# CORE_PRM register map
Vendor: Texas Instruments
Peripheral module from a debugger description file (folder omap4430).
Registers are 32-bit, access not given, reset 0x3 unless marked. A register's access mark holds for its fields unless they carry their own. Offsets are as the file gives them; lines under a group give offsets from that group; [hi:lo] are bit positions; {n}, {i} and the like mark numbered series; 'fields as' and 'values as' point back to an identical list; <NAME> marks a mode.

## CORE_PRM
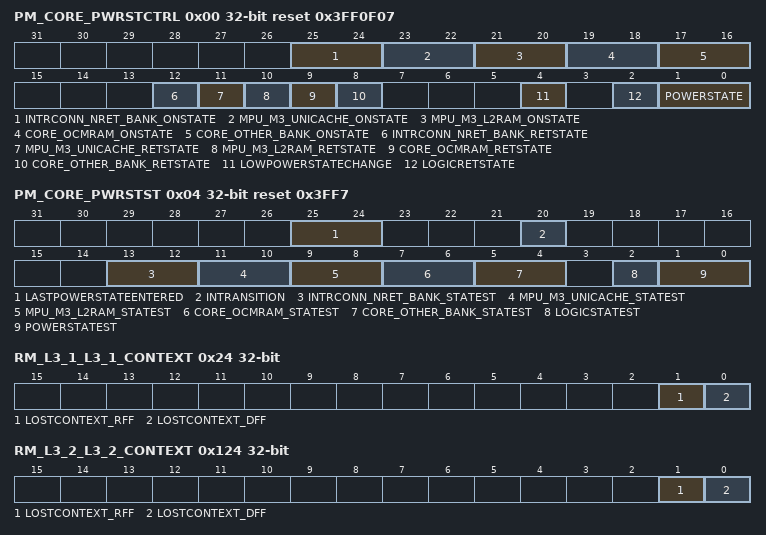
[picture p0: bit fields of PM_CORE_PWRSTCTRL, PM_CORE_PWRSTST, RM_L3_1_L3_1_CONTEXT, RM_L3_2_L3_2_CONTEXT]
0x00 PM_CORE_PWRSTCTRL reset 0x3FF0F07 — This register controls the CORE power state to reach upon a domain sleep transition
  [25:24] INTRCONN_NRET_BANK_ONSTATE — INTRCONN_WP bank and DMM bank2 state when domain is ON. (access R Rreturns1s)
    3=INTRCONN_NRET_BANK_ONSTATE_3_r (Memory bank is on when the domain is ON.)
  [23:22] MPU_M3_UNICACHE_ONSTATE — MPU_A3 UNICACHE bank state when domain is ON. (access R Rreturns1s)
    3=MPU_M3_UNICACHE_ONSTATE_3_r (Memory bank is on when the domain is ON.)
  [21:20] MPU_M3_L2RAM_ONSTATE — MPU_A3 L2 bank state when domain is ON. (access R Rreturns1s)
    3=MPU_M3_L2RAM_ONSTATE_3_r (Memory bank is on when the domain is ON.)
  [19:18] CORE_OCMRAM_ONSTATE — OCMRAM bank state when domain is ON. (access R Rreturns1s)
    3=CORE_OCMRAM_ONSTATE_3_r (Memory bank is on when the domain is ON.)
  [17:16] CORE_OTHER_BANK_ONSTATE — DMA/ICR bank and DMM bank1 state when domain is ON. (access R Rreturns1s)
    3=CORE_OTHER_BANK_ONSTATE_3_r (Memory bank is on when the domain is ON.)
  [12] INTRCONN_NRET_BANK_RETSTATE ro — INTRCONN_WP bank and DMM bank2 state when domain is RETENTION.
    0=INTRCONN_NRET_BANK_RETSTATE_0_r (Memory bank is off when the domain is in the RETENTION state.)
  [11] MPU_M3_UNICACHE_RETSTATE rw — MPU_A3 UNICACHE bank state when domain is RETENTION.
    0=Memory bank is off when the domain is in the RETENTION state; 1=Memory bank is retained when domain is in RETENTION state
  [10] MPU_M3_L2RAM_RETSTATE rw — MPU_A3 L2 bank state when domain is RETENTION.
    values as MPU_M3_UNICACHE_RETSTATE
  [9] CORE_OCMRAM_RETSTATE — OCMRAM bank state when domain is RETENTION. (access R Rreturns1s)
    1=CORE_OCMRAM_RETSTATE_1_r (Memory bank is retained when domain is in RETENTION state.)
  [8] CORE_OTHER_BANK_RETSTATE — DMA/ICR bank and DMM bank1 state when domain is RETENTION. (access R Rreturns1s)
    1=CORE_OTHER_BANK_RETSTATE_1_r (Memory bank is retained when domain is in RETENTION state.)
  [4] LOWPOWERSTATECHANGE — Power state change request when domain has already performed a sleep transition. Allows going into deeper low power state without waking up the power domain. (access RW WSpecial)
    0=Do not request a low power state change; 1=Request a low power state change. This bit is automatically cleared when the power state is effectively changed or when power state is ON.
  [2] LOGICRETSTATE rw — Logic state when power domain is RETENTION
    0=Only retention registers are retained and remaing logic is off when the domain is in RETENTION state; 1=Whole logic is retained when domain is in RETENTION state
  [1:0] POWERSTATE rw — Power state control
    0=POWERSTATE_0_r (Reserved); 1=RETENTION state; 2=INACTIVE state; 3=ON State
0x04 PM_CORE_PWRSTST reset 0x3FF7 — This register provides a status on the current CORE power domain state. [warm reset insensitive]
  [25:24] LASTPOWERSTATEENTERED — Last low power state entered. Set to 0x3 upon write of the same only. This register is intended for debug purpose only. (access RW W1toSet)
    3=LASTPOWERSTATEENTERED_3_r (Power domain was previously ON-ACTIVE); 2=LASTPOWERSTATEENTERED_2_r (Power domain was previously ON-INACTIVE); 1=LASTPOWERSTATEENTERED_1_r (Power domain was previously in RETENTION); 0=LASTPOWERSTATEENTERED_0_r (Power domain was previously OFF)
  [20] INTRANSITION ro — Domain transition status
    0=INTRANSITION_0_r (No ongoing transition on power domain); 1=INTRANSITION_1_r (Power domain transition is in progress.)
  [13:12] INTRCONN_NRET_BANK_STATEST ro — INTRCONN_WP bank and DMM bank2 state status
    0=INTRCONN_NRET_BANK_STATEST_0_r (Memory is OFF); 1=INTRCONN_NRET_BANK_STATEST_1_r (Reserved); 2=INTRCONN_NRET_BANK_STATEST_2_r (Reserved); 3=INTRCONN_NRET_BANK_STATEST_3_r (Memory is ON)
  [11:10] MPU_M3_UNICACHE_STATEST ro — MPU_A3 UNICACHE bank state status
    0=MPU_M3_UNICACHE_STATEST_0_r (Memory is OFF); 1=MPU_M3_UNICACHE_STATEST_1_r (Memory is RETENTION); 2=MPU_M3_UNICACHE_STATEST_2_r (Reserved); 3=MPU_M3_UNICACHE_STATEST_3_r (Memory is ON)
  [9:8] MPU_M3_L2RAM_STATEST ro — MPU_A3 L2 bank state status
    0=MPU_M3_L2RAM_STATEST_0_r (Memory is OFF); 1=MPU_M3_L2RAM_STATEST_1_r (Memory is RETENTION); 2=MPU_M3_L2RAM_STATEST_2_r (Reserved); 3=MPU_M3_L2RAM_STATEST_3_r (Memory is ON)
  [7:6] CORE_OCMRAM_STATEST ro — OCMRAM bank state status
    0=CORE_OCMRAM_STATEST_0_r (Memory is OFF); 1=CORE_OCMRAM_STATEST_1_r (Memory is RETENTION); 2=CORE_OCMRAM_STATEST_2_r (Reserved); 3=CORE_OCMRAM_STATEST_3_r (Memory is ON)
  [5:4] CORE_OTHER_BANK_STATEST ro — DMA/ICR bank and DMM bank1 state status
    0=CORE_OTHER_BANK_STATEST_0_r (Memory is OFF); 1=CORE_OTHER_BANK_STATEST_1_r (Memory is RETENTION); 2=CORE_OTHER_BANK_STATEST_2_r (Reserved); 3=CORE_OTHER_BANK_STATEST_3_r (Memory is ON)
  [2] LOGICSTATEST ro — Logic state status
    0=LOGICSTATEST_0_r (Logic in domain is OFF); 1=LOGICSTATEST_1_r (Logic in domain is ON)
  [1:0] POWERSTATEST ro — Current power state status
    0=POWERSTATEST_0_r (Reserved); 1=POWERSTATEST_1_r (Power domain is in RETENTION); 2=POWERSTATEST_2_r (Power domain is ON-INACTIVE); 3=POWERSTATEST_3_r (Power domain is ON-ACTIVE)
0x24 RM_L3_1_L3_1_CONTEXT — This register contains dedicated L3_1 context statuses. [warm reset insensitive]
  [1] LOSTCONTEXT_RFF — Specify if RFF-based context has been lost due to a previous power transition or other reset source. (set upon assertion of CORE_PWRON_RET_RST signal) (access RW W1toClr)
    0=Context has been maintained; 1=Context has been lost
  [0] LOSTCONTEXT_DFF — Specify if DFF-based context has been lost due to a previous power transition or other reset source. (set upon assertion of CORE_RST signal) (access RW W1toClr)
    0=Context has been maintained; 1=Context has been lost
0x124 RM_L3_2_L3_2_CONTEXT — This register contains dedicated L3_2 context statuses. [warm reset insensitive]
  fields as RM_L3_1_L3_1_CONTEXT
0x12C RM_L3_2_GPMC_CONTEXT reset 0x2 — This register contains dedicated GPMC context statuses. [warm reset insensitive]
  [1] LOSTCONTEXT_RFF — Specify if RFF-based context has been lost due to a previous power transition or other reset source. (set upon assertion of CORE_RET_RST signal) (access RW W1toClr)
    0=Context has been maintained; 1=Context has been lost
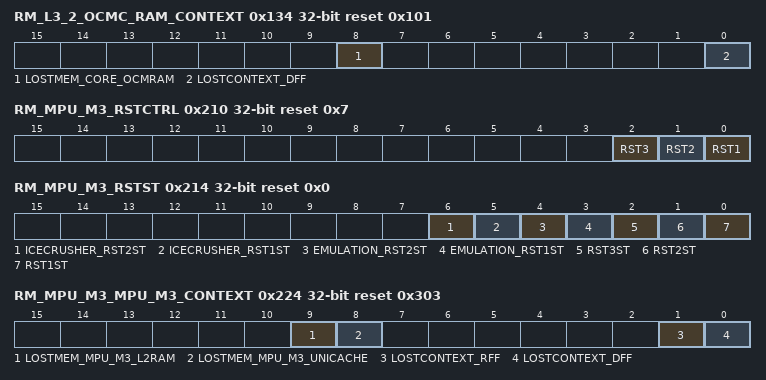
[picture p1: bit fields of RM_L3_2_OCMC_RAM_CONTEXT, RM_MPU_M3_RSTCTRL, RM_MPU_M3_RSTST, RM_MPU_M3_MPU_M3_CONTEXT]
0x134 RM_L3_2_OCMC_RAM_CONTEXT reset 0x101 — This register contains dedicated OCMC_RAM context statuses. [warm reset insensitive]
  [8] LOSTMEM_CORE_OCMRAM — Specify if memory-based context in CORE_OCMRAM memory bank has been lost due to a previous power transition or other reset source (not affected by a global warm reset). (access RW W1toClr)
    0=Context has been maintained; 1=Context has been lost
  [0] LOSTCONTEXT_DFF — Specify if DFF-based context has been lost due to a previous power transition or other reset source. (set upon assertion of CORE_RST signal) (access RW W1toClr)
    0=Context has been maintained; 1=Context has been lost
0x210 RM_MPU_M3_RSTCTRL access per field reset 0x7 — This register controls the release of the MPU_A3 sub-system resets.
  [2] RST3 rw — MPU_A3 MMU and CACHE interface reset control.
    0=Reset is cleared for MPU_A3 CACHE and MMU; 1=Reset is asserted for the MPU_A3 CACHE and MMU
  [1] RST2 rw — MPU_A3 Cortex M3 CPU2 reset control.
    0=Reset is cleared for the MPU_A3 Cortex M3 CPU2; 1=Reset is asserted for the MPU_A3 Cortex M3 CPU2
  [0] RST1 rw — MPU_A3 Cortex M3 CPU1 reset control.
    0=Reset is cleared for the MPU_A3 Cortex M3 CPU1; 1=Reset is asserted for the MPU_A3 Cortex M3 CPU1
0x214 RM_MPU_M3_RSTST reset 0x0 — This register logs the different reset sources of the MPU_A3 SS. Each bit is set upon release of the domain reset signal. Must be cleared by software. [warm reset insensitive]
  [6] ICECRUSHER_RST2ST — Cortex M3 CPU2 has been reset due to MPU_A3 ICECRUSHER2 reset source (access RW W1toClr)
    0=No icecrusher reset; 1=CPU2 has been reset upon icecrusher reset
  [5] ICECRUSHER_RST1ST — Cortex M3 CPU1 has been reset due to MPU_A3 ICECRUSHER1 reset source (access RW W1toClr)
    0=No icecrusher reset; 1=CPU1 has been reset upon icecrusher reset
  [4] EMULATION_RST2ST — Cortex M3 CPU2 has been reset due to emulation reset source, that is, assert reset command initiated by the icepick module (access RW W1toClr)
    0=No emulation reset; 1=CPU2 has been reset upon emulation reset
  [3] EMULATION_RST1ST — Cortex M3 CPU1 has been reset due to emulation reset source, that is, assert reset command initiated by the icepick module (access RW W1toClr)
    0=No emulation reset; 1=CPU1 has been reset upon emulation reset
  [2] RST3ST — MPU_A3 MMU and CACHE interface software reset status (access RW W1toClr)
    0=No software reset occured; 1=MPU_A3 MMU and CACHE interface has been reset upon software reset
  [1] RST2ST — MPU_A3 Cortex-M3 CPU2 software reset status (access RW W1toClr)
    0=No software reset occured; 1=Cortex M3 CPU2 has been reset upon software reset
  [0] RST1ST — MPU_A3 Cortex-M3 CPU1 software reset status (access RW W1toClr)
    0=No software reset occured; 1=Cortex M3 CPU1 has been reset upon software reset
0x224 RM_MPU_M3_MPU_M3_CONTEXT reset 0x303 — This register contains dedicated MPU_A3 context statuses. [warm reset insensitive]
  [all] fields
    0=Context has been maintained; 1=Context has been lost
  [9] LOSTMEM_MPU_M3_L2RAM — Specify if memory-based context in MPU_A3_L2RAM memory bank has been lost due to a previous power transition or other reset source. (access RW W1toClr)
  [8] LOSTMEM_MPU_M3_UNICACHE — Specify if memory-based context in MPU_A3_UNICACHE memory bank has been lost due to a previous power transition or other reset source. (access RW W1toClr)
  [1] LOSTCONTEXT_RFF — Specify if RFF-based context has been lost due to a previous power transition or other reset source. (set upon assertion of MPU_A3_RET_RST signal) (access RW W1toClr)
  [0] LOSTCONTEXT_DFF — Specify if DFF-based context has been lost due to a previous power transition or other reset source. (set upon assertion of MPU_A3_RST3 signal) (access RW W1toClr)
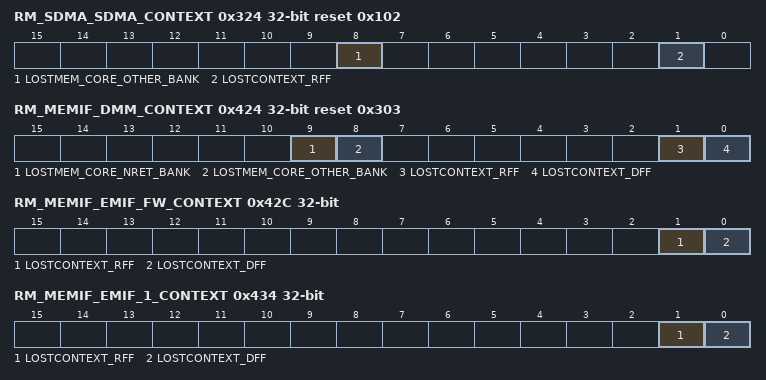
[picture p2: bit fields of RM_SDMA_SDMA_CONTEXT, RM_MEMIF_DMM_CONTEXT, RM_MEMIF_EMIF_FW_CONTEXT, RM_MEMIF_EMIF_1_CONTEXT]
0x324 RM_SDMA_SDMA_CONTEXT reset 0x102 — This register contains dedicated SDMA context statuses. [warm reset insensitive]
  [8] LOSTMEM_CORE_OTHER_BANK — Specify if memory-based context in CORE_OTHER_BANK memory bank has been lost due to a previous power transition or other reset source. (access RW W1toClr)
    0=Context has been maintained; 1=Context has been lost
  [1] LOSTCONTEXT_RFF — Specify if RFF-based context has been lost due to a previous power transition or other reset source. (set upon assertion of SDMA_RET_RST signal) (access RW W1toClr)
    0=Context has been maintained; 1=Context has been lost
0x424 RM_MEMIF_DMM_CONTEXT reset 0x303 — This register contains dedicated DMM context statuses. [warm reset insensitive]
  [all] fields
    0=Context has been maintained; 1=Context has been lost
  [9] LOSTMEM_CORE_NRET_BANK — Specify if memory-based context in CORE_NRET_BANK memory bank has been lost due to a previous power transition or other reset source. (access RW W1toClr)
  [8] LOSTMEM_CORE_OTHER_BANK — Specify if memory-based context in CORE_OTHER_BANK memory bank has been lost due to a previous power transition or other reset source. (access RW W1toClr)
  [1] LOSTCONTEXT_RFF — Specify if RFF-based context has been lost due to a previous power transition or other reset source. (set upon assertion of CORE_RET_RST signal) (access RW W1toClr)
  [0] LOSTCONTEXT_DFF — Specify if DFF-based context has been lost due to a previous power transition or other reset source. (set upon assertion of CORE_RST signal) (access RW W1toClr)
0x42C RM_MEMIF_EMIF_FW_CONTEXT — This register contains dedicated EMIF_FW context statuses. [warm reset insensitive]
  fields as RM_L3_1_L3_1_CONTEXT
0x434 RM_MEMIF_EMIF_1_CONTEXT — This register contains dedicated EMIF_1 context statuses. [warm reset insensitive]
  [1] LOSTCONTEXT_RFF — Specify if RFF-based context has been lost due to a previous power transition or other reset source. (set upon assertion of CORE_PWRON_RET_RST signal) (access RW W1toClr)
    0=Context has been maintained; 1=Context has been lost
  [0] LOSTCONTEXT_DFF — Specify if DFF-based context has been lost due to a previous power transition or other reset source. (set upon assertion of CORE_PWRON_RST signal) (access RW W1toClr)
    0=Context has been maintained; 1=Context has been lost
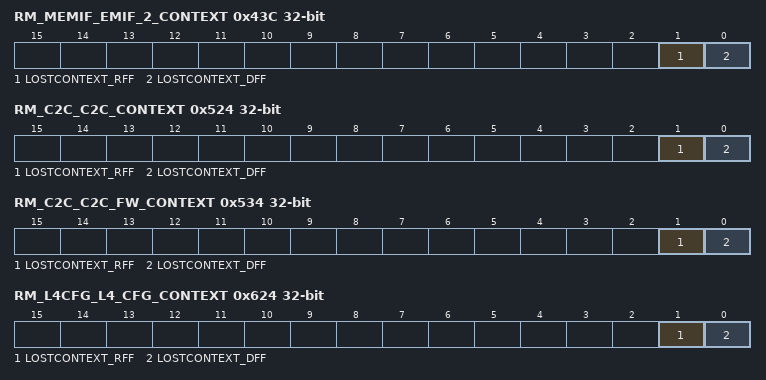
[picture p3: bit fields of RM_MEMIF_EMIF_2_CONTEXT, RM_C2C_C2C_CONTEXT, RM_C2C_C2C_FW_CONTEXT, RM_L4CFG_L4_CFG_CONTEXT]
0x43C RM_MEMIF_EMIF_2_CONTEXT — This register contains dedicated EMIF_2 context statuses. [warm reset insensitive]
  fields as RM_MEMIF_EMIF_1_CONTEXT
0x444 RM_MEMIF_DLL_CONTEXT reset 0x1 — This register contains dedicated DLL context statuses. [warm reset insensitive]
  [0] LOSTCONTEXT_DFF — Specify if DFF-based context has been lost due to a previous power transition or other reset source. (set upon assertion of DLL_RST signal) (access RW W1toClr)
    0=Context has been maintained; 1=Context has been lost
0x524 RM_C2C_C2C_CONTEXT — This register contains dedicated C2C context statuses. [warm reset insensitive]
  [1] LOSTCONTEXT_RFF — Specify if RFF-based context has been lost due to a previous power transition or other reset source. (set upon assertion of CORE_RST signal) (access RW W1toClr)
    0=Context has been maintained; 1=Context has been lost
  [0] LOSTCONTEXT_DFF — Specify if DFF-based context has been lost due to a previous power transition or other reset source. (set upon assertion of CORE_RST signal) (access RW W1toClr)
    0=Context has been maintained; 1=Context has been lost
0x534 RM_C2C_C2C_FW_CONTEXT — This register contains dedicated C2C_FW context statuses. [warm reset insensitive]
  fields as RM_L3_1_L3_1_CONTEXT
0x624 RM_L4CFG_L4_CFG_CONTEXT — This register contains dedicated L4_CFG context statuses. [warm reset insensitive]
  fields as RM_L3_1_L3_1_CONTEXT
0x62C RM_L4CFG_SPINLOCK_CONTEXT reset 0x2 — This register contains dedicated HW_SEM context statuses. [warm reset insensitive]
  fields as RM_L3_2_GPMC_CONTEXT
0x634 RM_L4CFG_MAILBOX_CONTEXT reset 0x2 — This register contains dedicated MAILBOX context statuses. [warm reset insensitive]
  fields as RM_L3_2_GPMC_CONTEXT
0x63C RM_L4CFG_SAR_ROM_CONTEXT reset 0x1 — This register contains dedicated SAR_ROM context statuses. [warm reset insensitive]
  [0] LOSTCONTEXT_DFF — Specify if DFF-based context has been lost due to a previous power transition or other reset source. (set upon assertion of CORE_RST signal) (access RW W1toClr)
    0=Context has been maintained; 1=Context has been lost
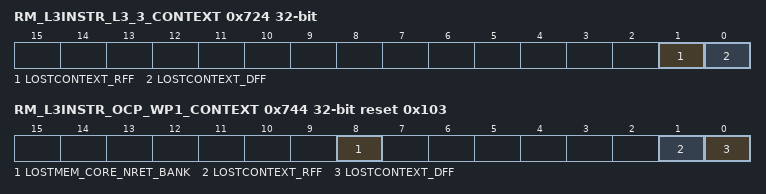
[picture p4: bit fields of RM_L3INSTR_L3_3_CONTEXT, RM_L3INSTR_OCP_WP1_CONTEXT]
0x724 RM_L3INSTR_L3_3_CONTEXT — This register contains dedicated L3_3 context statuses. [warm reset insensitive]
  fields as RM_L3_1_L3_1_CONTEXT
0x72C RM_L3INSTR_L3_INSTR_CONTEXT reset 0x1 — This register contains dedicated L3_INSTR context statuses. [warm reset insensitive]
  fields as RM_L4CFG_SAR_ROM_CONTEXT
0x744 RM_L3INSTR_OCP_WP1_CONTEXT reset 0x103 — This register contains dedicated OCP_WP1 context statuses. [warm reset insensitive]
  [all] fields
    0=Context has been maintained; 1=Context has been lost
  [8] LOSTMEM_CORE_NRET_BANK — Specify if memory-based context in CORE_NRET_BANK memory bank has been lost due to a previous power transition or other reset source. (access RW W1toClr)
  [1] LOSTCONTEXT_RFF — Specify if RFF-based context has been lost due to a previous power transition or other reset source. (set upon assertion of CORE_PWRON_RET_RST signal) (access RW W1toClr)
  [0] LOSTCONTEXT_DFF — Specify if DFF-based context has been lost due to a previous power transition or other reset source. (set upon assertion of CORE_RST signal) (access RW W1toClr)
